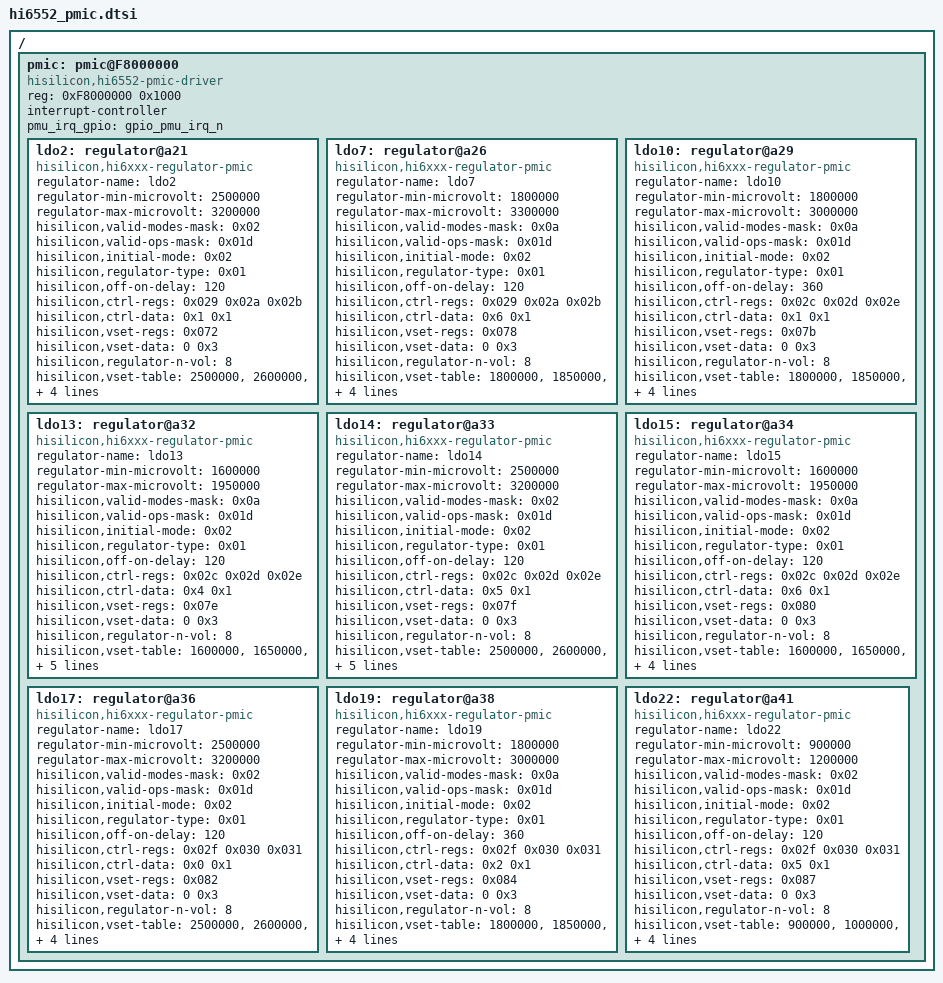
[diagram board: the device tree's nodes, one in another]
/******************************************************************************

                  版权所有 (C), 2001-2011, 华为技术有限公司

 ******************************************************************************
 
  This is an AUTO GENERATED file ! DON'T MODIFY MANUAL! 
  文 件 名   : %(filename)s
  生成日期   : %(year)d年%(month)d月%(day)d日
  
******************************************************************************/

/ {
	pmic: pmic@F8000000 {
		compatible = "hisilicon,hi6552-pmic-driver";
		reg = <0xF8000000 0x1000>;
		#interrupt-cells = <2>;
		interrupt-controller;
        pmu_irq_gpio = <&gpio_pmu_irq_n>;
		/*clocks = <&pmic_clk>;
		clock-names = "pmic_clk";*/


     ldo2: regulator@a21 {
			compatible = "hisilicon,hi6xxx-regulator-pmic";	
			regulator-name = "ldo2";
			regulator-min-microvolt = <2500000>;
			regulator-max-microvolt = <3200000>;
			hisilicon,valid-modes-mask = <0x02>;
			hisilicon,valid-ops-mask = <0x01d>;
			hisilicon,initial-mode = <0x02>;
			hisilicon,regulator-type = <0x01>;
			
			hisilicon,off-on-delay = <120>;
			hisilicon,ctrl-regs = <0x029 0x02a 0x02b>;
			hisilicon,ctrl-data = <0x1 0x1>;
			hisilicon,vset-regs = <0x072>;
			hisilicon,vset-data = <0 0x3>;
			hisilicon,regulator-n-vol = <8>;
			hisilicon,vset-table = <2500000>,<2600000>,<2700000>,<2800000>,<2900000>,<3000000>,<3100000>,<3200000>;
			hisilicon,num_consumer_supplies = <1>;
			hisilicon,consumer-supplies = "sensor_analog";
		};	

     ldo7: regulator@a26 {
			compatible = "hisilicon,hi6xxx-regulator-pmic";	
			regulator-name = "ldo7";
			regulator-min-microvolt = <1800000>;
			regulator-max-microvolt = <3300000>;
			hisilicon,valid-modes-mask = <0x0a>;
			hisilicon,valid-ops-mask = <0x01d>;
			hisilicon,initial-mode = <0x02>;
			hisilicon,regulator-type = <0x01>;
			
			hisilicon,off-on-delay = <120>;
			hisilicon,ctrl-regs = <0x029 0x02a 0x02b>;
			hisilicon,ctrl-data = <0x6 0x1>;
			hisilicon,vset-regs = <0x078>;
			hisilicon,vset-data = <0 0x3>;
			hisilicon,regulator-n-vol = <8>;
			hisilicon,vset-table = <1800000>,<1850000>,<2850000>,<2900000>,<3000000>,<3100000>,<3200000>,<3300000>;
			hisilicon,num_consumer_supplies = <1>;
			hisilicon,consumer-supplies = "sd_card_io";
		};	

     ldo10: regulator@a29 {
			compatible = "hisilicon,hi6xxx-regulator-pmic";	
			regulator-name = "ldo10";
			regulator-min-microvolt = <1800000>;
			regulator-max-microvolt = <3000000>;
			hisilicon,valid-modes-mask = <0x0a>;
			hisilicon,valid-ops-mask = <0x01d>;
			hisilicon,initial-mode = <0x02>;
			hisilicon,regulator-type = <0x01>;
			
			hisilicon,off-on-delay = <360>;
			hisilicon,ctrl-regs = <0x02c 0x02d 0x02e>;
			hisilicon,ctrl-data = <0x1 0x1>;
			hisilicon,vset-regs = <0x07b>;
			hisilicon,vset-data = <0 0x3>;
			hisilicon,regulator-n-vol = <8>;
			hisilicon,vset-table = <1800000>,<1850000>,<1900000>,<2750000>,<2800000>,<2850000>,<2900000>,<3000000>;
			hisilicon,num_consumer_supplies = <1>;
			hisilicon,consumer-supplies = "sd_card";
		};	

     ldo13: regulator@a32 {
			compatible = "hisilicon,hi6xxx-regulator-pmic";	
			regulator-name = "ldo13";
			regulator-min-microvolt = <1600000>;
			regulator-max-microvolt = <1950000>;
			hisilicon,valid-modes-mask = <0x0a>;
			hisilicon,valid-ops-mask = <0x01d>;
			hisilicon,initial-mode = <0x02>;
			hisilicon,regulator-type = <0x01>;
			
			hisilicon,off-on-delay = <120>;
			hisilicon,ctrl-regs = <0x02c 0x02d 0x02e>;
			hisilicon,ctrl-data = <0x4 0x1>;
			hisilicon,vset-regs = <0x07e>;
			hisilicon,vset-data = <0 0x3>;
			hisilicon,regulator-n-vol = <8>;
			hisilicon,vset-table = <1600000>,<1650000>,<1700000>,<1750000>,<1800000>,<1850000>,<1900000>,<1950000>;
			hisilicon,num_consumer_supplies = <3>;
			hisilicon,consumer-supplies = "scamera_core","mcamera_io","scamera_io";
		};	

     ldo14: regulator@a33 {
			compatible = "hisilicon,hi6xxx-regulator-pmic";	
			regulator-name = "ldo14";
			regulator-min-microvolt = <2500000>;
			regulator-max-microvolt = <3200000>;
			hisilicon,valid-modes-mask = <0x02>;
			hisilicon,valid-ops-mask = <0x01d>;
			hisilicon,initial-mode = <0x02>;
			hisilicon,regulator-type = <0x01>;
			
			hisilicon,off-on-delay = <120>;
			hisilicon,ctrl-regs = <0x02c 0x02d 0x02e>;
			hisilicon,ctrl-data = <0x5 0x1>;
			hisilicon,vset-regs = <0x07f>;
			hisilicon,vset-data = <0 0x3>;
			hisilicon,regulator-n-vol = <8>;
			hisilicon,vset-table = <2500000>,<2600000>,<2700000>,<2800000>,<2900000>,<3000000>,<3100000>,<3200000>;
			hisilicon,num_consumer_supplies = <3>;
			hisilicon,consumer-supplies = "scamera_avdd","mcamera_avdd","mcamera_vcm";
		};	

     ldo15: regulator@a34 {
			compatible = "hisilicon,hi6xxx-regulator-pmic";	
			regulator-name = "ldo15";
			regulator-min-microvolt = <1600000>;
			regulator-max-microvolt = <1950000>;
			hisilicon,valid-modes-mask = <0x0a>;
			hisilicon,valid-ops-mask = <0x01d>;
			hisilicon,initial-mode = <0x02>;
			hisilicon,regulator-type = <0x01>;
			
			hisilicon,off-on-delay = <120>;
			hisilicon,ctrl-regs = <0x02c 0x02d 0x02e>;
			hisilicon,ctrl-data = <0x6 0x1>;
			hisilicon,vset-regs = <0x080>;
			hisilicon,vset-data = <0 0x3>;
			hisilicon,regulator-n-vol = <8>;
			hisilicon,vset-table = <1600000>,<1650000>,<1700000>,<1750000>,<1800000>,<1850000>,<1900000>,<1950000>;
			hisilicon,num_consumer_supplies = <1>;
			hisilicon,consumer-supplies = "codec_analog";
		};	

     ldo17: regulator@a36 {
			compatible = "hisilicon,hi6xxx-regulator-pmic";	
			regulator-name = "ldo17";
			regulator-min-microvolt = <2500000>;
			regulator-max-microvolt = <3200000>;
			hisilicon,valid-modes-mask = <0x02>;
			hisilicon,valid-ops-mask = <0x01d>;
			hisilicon,initial-mode = <0x02>;
			hisilicon,regulator-type = <0x01>;
			
			hisilicon,off-on-delay = <120>;
			hisilicon,ctrl-regs = <0x02f 0x030 0x031>;
			hisilicon,ctrl-data = <0x0 0x1>;
			hisilicon,vset-regs = <0x082>;
			hisilicon,vset-data = <0 0x3>;
			hisilicon,regulator-n-vol = <8>;
			hisilicon,vset-table = <2500000>,<2600000>,<2700000>,<2800000>,<2900000>,<3000000>,<3100000>,<3200000>;
			hisilicon,num_consumer_supplies = <1>;
			hisilicon,consumer-supplies = "vibrator";
		};	

     ldo19: regulator@a38 {
			compatible = "hisilicon,hi6xxx-regulator-pmic";	
			regulator-name = "ldo19";
			regulator-min-microvolt = <1800000>;
			regulator-max-microvolt = <3000000>;
			hisilicon,valid-modes-mask = <0x0a>;
			hisilicon,valid-ops-mask = <0x01d>;
			hisilicon,initial-mode = <0x02>;
			hisilicon,regulator-type = <0x01>;
			
			hisilicon,off-on-delay = <360>;
			hisilicon,ctrl-regs = <0x02f 0x030 0x031>;
			hisilicon,ctrl-data = <0x2 0x1>;
			hisilicon,vset-regs = <0x084>;
			hisilicon,vset-data = <0 0x3>;
			hisilicon,regulator-n-vol = <8>;
			hisilicon,vset-table = <1800000>,<1850000>,<1900000>,<2750000>,<2800000>,<2850000>,<2900000>,<3000000>;
			hisilicon,num_consumer_supplies = <1>;
			hisilicon,consumer-supplies = "emmc_vddm";
		};	

     ldo22: regulator@a41 {
			compatible = "hisilicon,hi6xxx-regulator-pmic";	
			regulator-name = "ldo22";
			regulator-min-microvolt = <900000>;
			regulator-max-microvolt = <1200000>;
			hisilicon,valid-modes-mask = <0x02>;
			hisilicon,valid-ops-mask = <0x01d>;
			hisilicon,initial-mode = <0x02>;
			hisilicon,regulator-type = <0x01>;
			
			hisilicon,off-on-delay = <120>;
			hisilicon,ctrl-regs = <0x02f 0x030 0x031>;
			hisilicon,ctrl-data = <0x5 0x1>;
			hisilicon,vset-regs = <0x087>;
			hisilicon,vset-data = <0 0x3>;
			hisilicon,regulator-n-vol = <8>;
			hisilicon,vset-table = <900000>,<1000000>,<1050000>,<1100000>,<1150000>,<1175000>,<1185000>,<1200000>;
			hisilicon,num_consumer_supplies = <1>;
			hisilicon,consumer-supplies = "mcamera_core";
		};	


	};	


 };	

